# STM32WL5X_CM0P register map
File version: 2.1
CPU: CM0 r0p1, little endian, MPU, no FPU, 4 interrupt priority bits
Registers are 32-bit, read-write, reset 0x0 unless marked. A register's access mark holds for its fields unless they carry their own. Offsets are from the block's base; [hi:lo] are bit positions; {n}, {i} and the like mark numbered series; 'fields as' and 'values as' point back to an identical list.

## SYSCFG — System configuration controller
Base 0x40010000
0x00 MEMRMP — memory remap register
  [2:0] MEM_MODE — Memory mapping selection
    0=Main Flash memory mapped at 0x0000_0000; 1=System Flash memory mapped at 0x0000_0000; 3=SRAM (Embedded SRAM mapped at 0x0000_0000)
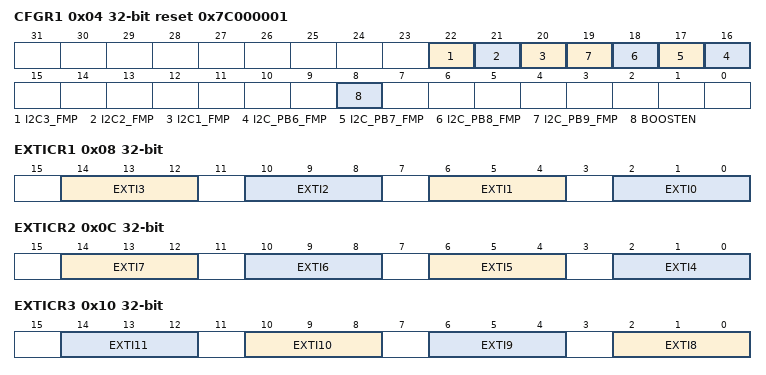
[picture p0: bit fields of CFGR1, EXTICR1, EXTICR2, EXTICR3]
0x04 CFGR1 reset 0x7C000001 — configuration register 1
  [22] I2C3_FMP — I2C3 Fast-mode Plus driving capability activation
    0=Standard (FM+ mode is controlled by I2C_Pxx_FMP bits only); 1=FMP (FM+ mode is enabled on all I2C3 pins selected through selection bits in GPIOx_AFR registers)
  [21] I2C2_FMP — I2C2 Fast-mode Plus driving capability activation
    0=Standard (FM+ mode is controlled by I2C_Pxx_FMP bits only); 1=FMP (FM+ mode is enabled on all I2C2 pins selected through selection bits in GPIOx_AFR registers)
  [20] I2C1_FMP — I2C1 Fast-mode Plus driving capability activation
    0=Standard (FM+ mode is controlled by I2C_Pxx_FMP bits only); 1=FMP (FM+ mode is enabled on all I2C1 pins selected through selection bits in GPIOx_AFR registers)
  [n+10] I2C_PB{n}_FMP (n=6..9) — Fast-mode Plus (Fm+) driving capability activation on PB{n}
    0=Standard (PB{n} pin operate in standard mode); 1=FMP (I2C FM+ mode enabled on PB{n} and the Speed control is bypassed)
  [8] BOOSTEN — I/O analog switch voltage booster enable
    0=Disabled (I/O analog switches are supplied by VDDA voltage. This is the recommended configuration when using the ADC in high VDDA voltage operation); 1=Enabled (I/O analog switches are supplied by a dedicated voltage booster (supplied by VDD). This is the recommended configuration when using the ADC in low VDDA voltage operation)
0x08 EXTICR1 — external interrupt configuration register 1
  [14:12] EXTI3 — EXTI 3 configuration bits
    0=PA (Select PAx as the source input for the EXTIx external interrupt); 1=PB (Select PBx as the source input for the EXTIx external interrupt); 2=PC (Select PCx as the source input for the EXTIx external interrupt); 7=PH (Select PHx as the source input for the EXTIx external interrupt)
  [10:8] EXTI2 — EXTI 2 configuration bits
    0=PA (Select PAx as the source input for the EXTIx external interrupt); 1=PB (Select PBx as the source input for the EXTIx external interrupt); 2=PC (Select PCx as the source input for the EXTIx external interrupt)
  [6:4] EXTI1 — EXTI 1 configuration bits
    values as EXTI2
  [2:0] EXTI0 — EXTI 0 configuration bits
    values as EXTI2
0x0C EXTICR2 — external interrupt configuration register 2
  [14:12] EXTI7 — EXTI 7 configuration bits
    0=PA (Select PAx as the source input for the EXTIx external interrupt); 1=PB (Select PBx as the source input for the EXTIx external interrupt)
  [10:8] EXTI6 — EXTI 6 configuration bits
    values as EXTICR1.EXTI2
  [6:4] EXTI5 — EXTI 5 configuration bits
    values as EXTICR1.EXTI2
  [2:0] EXTI4 — EXTI 4 configuration bits
    values as EXTICR1.EXTI2
0x10 EXTICR3 — external interrupt configuration register 3
  [all] fields
    values as EXTICR2.EXTI7
  [4n-30:4n-32] EXTI{n} (n=8..11) — EXTI {n} configuration bits
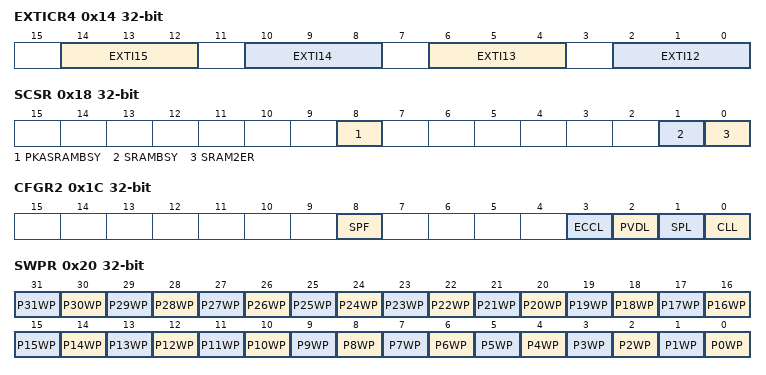
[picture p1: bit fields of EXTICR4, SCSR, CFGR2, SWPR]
0x14 EXTICR4 — external interrupt configuration register 4
  [14:12] EXTI15 — EXTI15 configuration bits
    values as EXTICR1.EXTI2
  [10:8] EXTI14 — EXTI14 configuration bits
    values as EXTICR1.EXTI2
  [6:4] EXTI13 — EXTI13 configuration bits
    values as EXTICR1.EXTI2
  [2:0] EXTI12 — EXTI12 configuration bits
    values as EXTICR2.EXTI7
0x18 SCSR access per field
  [8] PKASRAMBSY ro — PKA SRAM busy by erase operation
    0=Idle (No PKA SRAM erase operation is ongoing); 1=Busy (PKA SRAM erase operation is ongoing)
  [1] SRAMBSY ro — SRAM1, SRAM2 and PKA SRAM busy by erase operation
    0=Idle (No SRAM1 or SRAM2 erase operation is ongoing); 1=Busy (SRAM1 or SRAM2 erase operation is ongoing)
  [0] SRAM2ER rw — SRAM2 erase
    on write: 1=Erase (Start SRAM2 erase operation)
0x1C CFGR2
  [8] SPF — SRAM2 parity error flag
    on read: 0=Nominal (No SRAM2 parity error detected); 1=Error (SRAM2 parity error detected) | on write: 1=Clear SRAM2 parity error flag
  [3] ECCL — ECC Lock
    on read: 0=Disconnected (ECC error disconnected from TIM1/16/17 break input); 1=Connected (ECC error connected to TIM1/16/17 break input) | on write: 1=Connect ECC error to TIM1/16/17 break input
  [2] PVDL — PVD lock enable bit
    on read: 0=Disconnected (PVD interrupt disconnected from TIM1/16/17 break input. PVDE and PLS[2:0] bits can be programmed by the application); 1=Connected (PVD interrupt connected to TIM1/16/17 break input. PVDE and PLS[2:0] bits are read only) | on write: 1=Connect PVD interretup to TIM1/16/17 break input
  [1] SPL — SRAM2 parity lock bit
    on read: 0=Disconnected (SRAM2 parity error signal disconnected from TIM1/16/17 break input); 1=Connected (SRAM2 parity error signal connected to TIM1/16/17 break input) | on write: 1=Connect SRAM2 parity error signal to TIM1/16/17 break input
  [0] CLL — CPU1 LOCKUP (Hardfault) output enable bit
    on read: 0=Disconnected (CPU LOCKUP output disconnected from TIM1/16/17 break input); 1=Connected (CPU LOCKUP output connected to TIM1/16/17 break input) | on write: 1=Connect CPU LOCKUP output to TIM1/16/17 break input
0x20 SWPR
  [all] fields
    0=Disabled (SRAM2 1 KB page protection disabled); 1=Enabled (SRAM2 1 KB page protection enabled)
  [n] P{n}WP (n=0..31) — SRAM2 1Kbyte page {n} write protection
0x24 SKR wo
  [7:0] KEY — SRAM2 write protection key for software erase
    17=WriteProtect (Activate SRAM2ER bits write protection); 83=Step 2 to remove SRAM2ER bits write protection; 202=Step 1 to remove SRAM2ER bits write protection
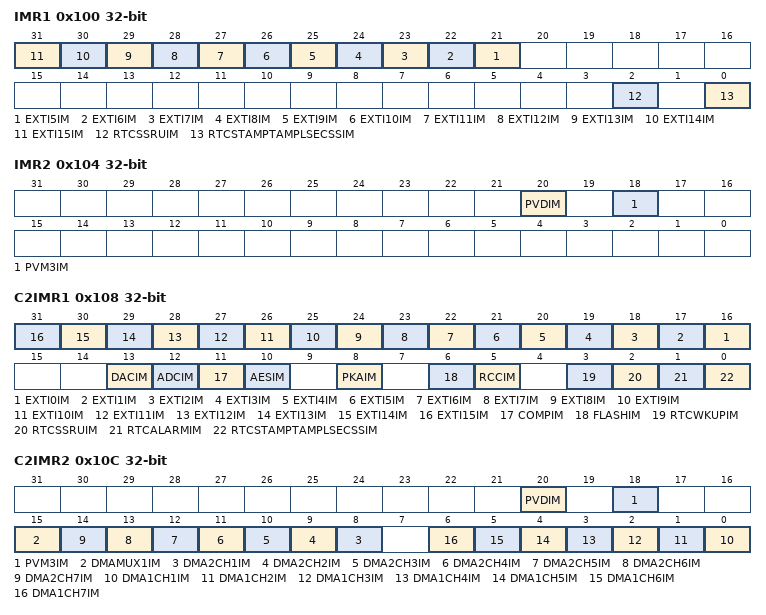
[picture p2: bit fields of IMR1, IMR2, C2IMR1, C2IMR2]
0x100 IMR1 — SYSCFG CPU1 interrupt mask register 1
  [n+16] EXTI{n}IM (n=5..15), [2] RTCSSRUIM, [0] RTCSTAMPTAMPLSECSSIM
0x104 IMR2 — SYSCFG CPU1 interrupt mask register 2
  [20] PVDIM, [18] PVM3IM
0x108 C2IMR1 — SYSCFG CPU2 interrupt mask register 1
  [n+16] EXTI{n}IM (n=0..15), [13] DACIM, [12] ADCIM, [11] COMPIM, [10] AESIM, [8] PKAIM, [6] FLASHIM, [5] RCCIM, [3] RTCWKUPIM, [2] RTCSSRUIM, [1] RTCALARMIM, [0] RTCSTAMPTAMPLSECSSIM
0x10C C2IMR2 — SYSCFG CPU2 interrupt mask register 2
  [20] PVDIM, [18] PVM3IM, [15] DMAMUX1IM, [n+7] DMA2CH{n}IM (n=1..7), [n-1] DMA1CH{n}IM (n=1..7)
0x208 RFDCR — radio debug control register
  [0] RFTBSEL — radio debug test bus selection
    0=Digital test bus selected on RF_ADTB[3:0]; 1=Analog test bus selected on RF_ADTB[3:0]
